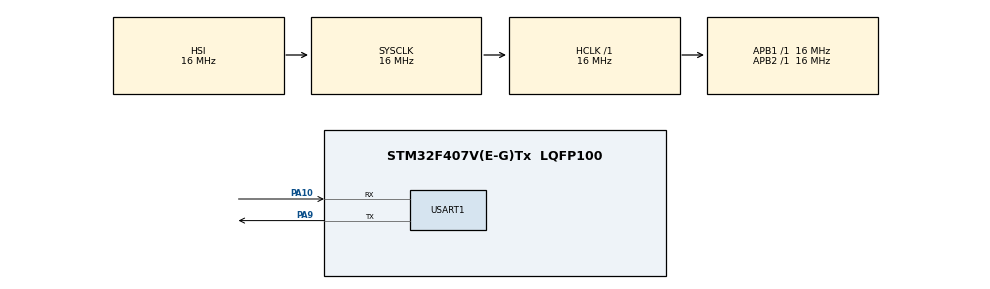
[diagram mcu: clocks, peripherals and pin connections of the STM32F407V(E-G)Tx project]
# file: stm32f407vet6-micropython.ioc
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FREERTOS.Tasks01=defaultTask,24,128,StartDefaultTask,Default,NULL,Dynamic,NULL,NULL
Mcu.Family=STM32F4
Mcu.Name=STM32F407V(E-G)Tx
Mcu.Package=LQFP100
NVIC.PriorityGroup=NVIC_PRIORITYGROUP_4
NVIC.TIM6_DAC_IRQn=true\:15\:0\:false\:false\:true\:false\:false\:true\:true
NVIC.TimeBase=TIM6_DAC_IRQn
NVIC.TimeBaseIP=TIM6
PA10.Mode=Asynchronous
PA10.Signal=USART1_RX
PA9.Mode=Asynchronous
PA9.Signal=USART1_TX
ProjectManager.HeapSize=0x200
ProjectManager.StackSize=0x400
ProjectManager.TargetToolchain=CMake
RCC.AHBFreq_Value=16000000
RCC.APB1Freq_Value=16000000
RCC.APB2Freq_Value=16000000
RCC.CortexFreq_Value=16000000
RCC.HSE_VALUE=25000000
RCC.HSI_VALUE=16000000
RCC.LSE_VALUE=32768
RCC.SYSCLKFreq_VALUE=16000000
RCC.VCOOutputFreq_Value=192000000
USART1.VirtualMode=VM_ASYNC
VP_FREERTOS_VS_CMSIS_V2.Mode=CMSIS_V2
VP_SYS_VS_tim6.Mode=TIM6
board=custom

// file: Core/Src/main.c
/* USER CODE BEGIN Header */
/**
  ******************************************************************************
  * @file           : main.c
  * @brief          : Main program body
  ******************************************************************************
  * @attention
  *
  * Copyright (c) 2025 STMicroelectronics.
  * All rights reserved.
  *
  * This software is licensed under terms that can be found in the LICENSE file
  * in the root directory of this software component.
  * If no LICENSE file comes with this software, it is provided AS-IS.
  *
  ******************************************************************************
  */
/* USER CODE END Header */
#include "main.h"
#include "cmsis_os.h"
#include "usart.h"
#include "gpio.h"

/* USER CODE BEGIN Includes */

#include "stdio.h"
#include <string.h>  // 需要 strlen

/* USER CODE END Includes */

void SystemClock_Config(void);
void MX_FREERTOS_Init(void);

int main(void)
{

  /* MCU Configuration--------------------------------------------------------*/

  /* Reset of all peripherals, Initializes the Flash interface and the Systick. */
  HAL_Init();

  /* Configure the system clock */
  SystemClock_Config();

  /* Initialize all configured peripherals */
  MX_GPIO_Init();
  MX_USART1_UART_Init();
  /* USER CODE BEGIN 2 */

  // 最早的测试输出 - 如果这个都没有，说明硬件有问题
  const char *test_msg = "\r\n=== STM32 System Started ===\r\n";
  HAL_UART_Transmit(&huart1, (uint8_t*)test_msg, strlen(test_msg), 1000);

  /* USER CODE END 2 */

  /* Init scheduler */
  osKernelInitialize();  /* Call init function for freertos objects (in cmsis_os2.c) */
  MX_FREERTOS_Init();

  /* Start scheduler */
  osKernelStart();

  /* We should never get here as control is now taken by the scheduler */

  /* Infinite loop */
  while (1)
  {

  }
}

void SystemClock_Config(void)
{
  RCC_OscInitTypeDef RCC_OscInitStruct = {0};
  RCC_ClkInitTypeDef RCC_ClkInitStruct = {0};

  /** Configure the main internal regulator output voltage
  */
  __HAL_RCC_PWR_CLK_ENABLE();
  __HAL_PWR_VOLTAGESCALING_CONFIG(PWR_REGULATOR_VOLTAGE_SCALE1);

  /** Initializes the RCC Oscillators according to the specified parameters
  * in the RCC_OscInitTypeDef structure.
  */
  RCC_OscInitStruct.OscillatorType = RCC_OSCILLATORTYPE_HSI;
  RCC_OscInitStruct.HSIState = RCC_HSI_ON;
  RCC_OscInitStruct.HSICalibrationValue = RCC_HSICALIBRATION_DEFAULT;
  RCC_OscInitStruct.PLL.PLLState = RCC_PLL_NONE;
  if (HAL_RCC_OscConfig(&RCC_OscInitStruct) != HAL_OK)
  {
    Error_Handler();
  }

  /** Initializes the CPU, AHB and APB buses clocks
  */
  RCC_ClkInitStruct.ClockType = RCC_CLOCKTYPE_HCLK|RCC_CLOCKTYPE_SYSCLK
                              |RCC_CLOCKTYPE_PCLK1|RCC_CLOCKTYPE_PCLK2;
  RCC_ClkInitStruct.SYSCLKSource = RCC_SYSCLKSOURCE_HSI;
  RCC_ClkInitStruct.AHBCLKDivider = RCC_SYSCLK_DIV1;
  RCC_ClkInitStruct.APB1CLKDivider = RCC_HCLK_DIV1;
  RCC_ClkInitStruct.APB2CLKDivider = RCC_HCLK_DIV1;

  if (HAL_RCC_ClockConfig(&RCC_ClkInitStruct, FLASH_LATENCY_0) != HAL_OK)
  {
    Error_Handler();
  }
}

void HAL_TIM_PeriodElapsedCallback(TIM_HandleTypeDef *htim)
{
  if (htim->Instance == TIM6)
  {
    HAL_IncTick();
  }
}

void Error_Handler(void)
{
  __disable_irq();
  while (1)
  {
  }
}

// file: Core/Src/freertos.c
/* USER CODE BEGIN Header */
/**
  ******************************************************************************
  * File Name          : freertos.c
  * Description        : Code for freertos applications
  ******************************************************************************
  * @attention
  *
  * Copyright (c) 2025 STMicroelectronics.
  * All rights reserved.
  *
  * This software is licensed under terms that can be found in the LICENSE file
  * in the root directory of this software component.
  * If no LICENSE file comes with this software, it is provided AS-IS.
  *
  ******************************************************************************
  */
/* USER CODE END Header */

#include "FreeRTOS.h"
#include "task.h"
#include "main.h"
#include "cmsis_os.h"
#include "app_main.h"

/* USER CODE BEGIN Includes */

#include "py/compile.h"
#include "py/runtime.h"
#include "py/gc.h"
#include "shared/runtime/pyexec.h"
#include "usart.h"  // 需要访问 huart1
#include <string.h> // 需要 strlen

/* USER CODE END Includes */

/* Definitions for defaultTask */
osThreadId_t defaultTaskHandle;
const osThreadAttr_t defaultTask_attributes = {
  .name = "defaultTask",
  .stack_size = 128 * 4,
  .priority = (osPriority_t) osPriorityNormal,
};

/* USER CODE BEGIN FunctionPrototypes */

// MicroPython 堆内存（静态分配）
static char micropython_heap[32 * 1024];  // 32KB

// MicroPython 任务函数
void MicroPythonTask(void *argument) {
    // 延迟一下，确保系统稳定启动
    osDelay(100);

    // 发送启动信息（直接用 HAL，确保输出）
    const char *msg = "\r\n=== MicroPython Starting ===\r\n";
    HAL_UART_Transmit(&huart1, (uint8_t*)msg, strlen(msg), HAL_MAX_DELAY);

    // 初始化 MicroPython
    gc_init(micropython_heap, micropython_heap + sizeof(micropython_heap));

    msg = "GC initialized\r\n";
    HAL_UART_Transmit(&huart1, (uint8_t*)msg, strlen(msg), HAL_MAX_DELAY);

    mp_init();

    msg = "MP initialized\r\n";
    HAL_UART_Transmit(&huart1, (uint8_t*)msg, strlen(msg), HAL_MAX_DELAY);

    // 启动 REPL
    for (;;) {
        if (pyexec_mode_kind == PYEXEC_MODE_RAW_REPL) {
            if (pyexec_raw_repl() != 0) {
                break;
            }
        } else {
            if (pyexec_friendly_repl() != 0) {
                break;
            }
        }
    }

    // 清理
    mp_deinit();
    osThreadTerminate(NULL);
}

/* 定义任务属性 */
const osThreadAttr_t micropython_task_attributes = {
    .name = "MicroPython",
    .stack_size = 4096 * 4,              // 16KB 堆栈（根据需要调整）
    .priority = (osPriority_t) osPriorityNormal,
};

// 任务句柄（可选，用于后续控制）
osThreadId_t micropythonTaskHandle;

/* USER CODE END FunctionPrototypes */

void StartDefaultTask(void *argument);

void MX_FREERTOS_Init(void); /* (MISRA C 2004 rule 8.1) */

void MX_FREERTOS_Init(void) {

  /* Create the thread(s) */
  /* creation of defaultTask */
  defaultTaskHandle = osThreadNew(StartDefaultTask, NULL, &defaultTask_attributes);

  /* USER CODE BEGIN RTOS_THREADS */
  /* add threads, ... */

  /* 创建 MicroPython 任务 */
  micropythonTaskHandle = osThreadNew(MicroPythonTask,
    NULL,
    &micropython_task_attributes);

  if (micropythonTaskHandle == NULL) {
  Error_Handler();  // 任务创建失败
  }
  /* USER CODE END RTOS_THREADS */

}

void StartDefaultTask(void *argument)
{
  /* USER CODE BEGIN StartDefaultTask */

  app_main();

  /* Infinite loop */
  for(;;)
  {
    osDelay(1);
  }
  /* USER CODE END StartDefaultTask */
}
